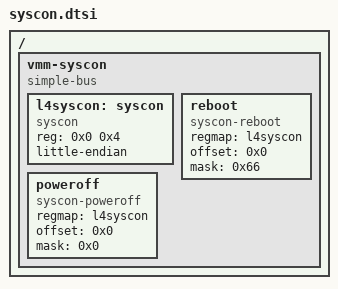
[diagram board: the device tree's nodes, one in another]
/**
 * L4 uvmm system management console. Provides reboot and poweroff hooks
 * towards the vmm.
 */

/ {
	vmm-syscon {
		#address-cells = <1>;
		#size-cells = <1>;
		compatible = "simple-bus";
		ranges = <0x0 0x30030000 0x4>;
		
		l4syscon: syscon {
			compatible = "syscon", "syscon-l4vmm";
			reg = <0x0 0x4>;
			little-endian;
		};
		
		reboot {
			compatible = "syscon-reboot";
			regmap = <&l4syscon>;
			offset = <0x0>;
			mask = <0x66>;
		};
		
		poweroff {
			compatible = "syscon-poweroff";
			regmap = <&l4syscon>;
			offset = <0x0>;
			mask = <0x0>;
		};
	};
};
